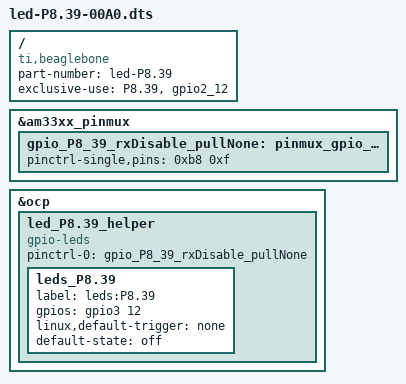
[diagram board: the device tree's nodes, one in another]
/*
* Easy gpio mux control of "P8.39" ("gpio2_12")
*/
/dts-v1/;
/plugin/;

/ {
	compatible = "ti,beaglebone", "ti,beaglebone-black";

	/* identification */
	part-number = "led-P8.39";
	/* version = "00A0"; */

	/* state the resources this cape uses */
	exclusive-use =
		/* the pin header uses */
		"P8.39",

		/* the hardware IP uses */
		"gpio2_12";
	
	
	/* rxDisable_pullNone state */
	fragment@0 {
		target = <&am33xx_pinmux>;
		__overlay__ {
			gpio_P8_39_rxDisable_pullNone: pinmux_gpio_P8.39_rxDisable_pullNone {
				pinctrl-single,pins = <
					0xb8 0xf
				>;
			};
		};
	};

	fragment@1 {
		target = <&ocp>;
		__overlay__ {
			led_P8.39_helper {
				compatible = "gpio-leds";
				pinctrl-names = "default";
				pinctrl-0 = <&gpio_P8_39_rxDisable_pullNone>;
				
				leds_P8.39 {
					label = "leds:P8.39";
					gpios = <&gpio3 12 0>;
					linux,default-trigger = "none";
					default-state = "off";
				};
			};
			
		};
	};

};
